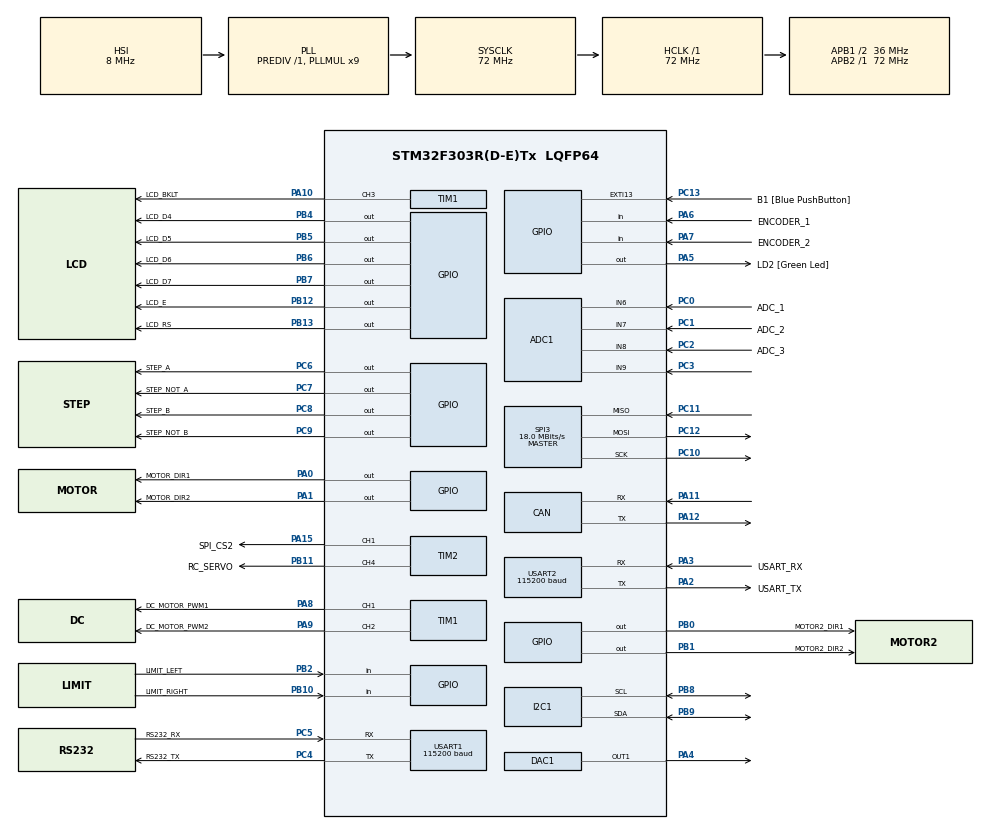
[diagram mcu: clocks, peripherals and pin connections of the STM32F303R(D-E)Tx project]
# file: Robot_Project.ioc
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ADC1.Channel-2\#ChannelRegularConversion=ADC_CHANNEL_6
ADC1.NbrOfConversionFlag=1
ADC1.Offset-2\#ChannelRegularConversion=0
ADC1.OffsetNumber-2\#ChannelRegularConversion=ADC_OFFSET_NONE
ADC1.Rank-2\#ChannelRegularConversion=1
ADC1.SamplingTime-2\#ChannelRegularConversion=ADC_SAMPLETIME_1CYCLE_5
ADC1.SingleDiff-2\#ChannelRegularConversion=ADC_DIFFERENTIAL_ENDED
ADC1.master=1
CAN.CalculateTimeQuantum=444.44444444444446
Dma.Request0=USART2_RX
Dma.Request1=USART1_RX
Dma.USART1_RX.1.Direction=DMA_PERIPH_TO_MEMORY
Dma.USART1_RX.1.Instance=DMA1_Channel5
Dma.USART1_RX.1.MemDataAlignment=DMA_MDATAALIGN_BYTE
Dma.USART1_RX.1.MemInc=DMA_MINC_ENABLE
Dma.USART1_RX.1.Mode=DMA_CIRCULAR
Dma.USART1_RX.1.PeriphDataAlignment=DMA_PDATAALIGN_BYTE
Dma.USART1_RX.1.PeriphInc=DMA_PINC_DISABLE
Dma.USART1_RX.1.Priority=DMA_PRIORITY_LOW
Dma.USART2_RX.0.Direction=DMA_PERIPH_TO_MEMORY
Dma.USART2_RX.0.Instance=DMA1_Channel6
Dma.USART2_RX.0.MemDataAlignment=DMA_MDATAALIGN_BYTE
Dma.USART2_RX.0.MemInc=DMA_MINC_ENABLE
Dma.USART2_RX.0.Mode=DMA_CIRCULAR
Dma.USART2_RX.0.PeriphDataAlignment=DMA_PDATAALIGN_BYTE
Dma.USART2_RX.0.PeriphInc=DMA_PINC_DISABLE
Dma.USART2_RX.0.Priority=DMA_PRIORITY_LOW
Mcu.Family=STM32F3
Mcu.Name=STM32F303R(D-E)Tx
Mcu.Package=LQFP64
NVIC.DMA1_Channel5_IRQn=true\:0\:0\:false\:false\:true\:false
NVIC.DMA1_Channel6_IRQn=true\:0\:0\:false\:false\:true\:false
NVIC.PriorityGroup=NVIC_PRIORITYGROUP_0
PA0.GPIO_Label=MOTOR_DIR1
PA0.Signal=GPIO_Output
PA1.GPIO_Label=MOTOR_DIR2
PA1.Signal=GPIO_Output
PA10.GPIO_Label=LCD_BKLT
PA10.Signal=S_TIM1_CH3
PA11.Mode=Master
PA11.Signal=CAN_RX
PA12.Mode=Master
PA12.Signal=CAN_TX
PA13.GPIO_Label=TMS
PA13.Mode=Serial_Wire
PA13.Signal=SYS_JTMS-SWDIO
PA14.GPIO_Label=TCK
PA14.Mode=Serial_Wire
PA14.Signal=SYS_JTCK-SWCLK
PA15.GPIO_Label=SPI_CS2
PA15.Signal=S_TIM2_CH1_ETR
PA2.GPIO_Label=USART_TX
PA2.GPIO_Mode=GPIO_MODE_AF_PP
PA2.GPIO_PuPd=GPIO_NOPULL
PA2.GPIO_Speed=GPIO_SPEED_FREQ_LOW
PA2.Mode=Asynchronous
PA2.Signal=USART2_TX
PA3.GPIO_Label=USART_RX
PA3.GPIO_Mode=GPIO_MODE_AF_PP
PA3.GPIO_PuPd=GPIO_NOPULL
PA3.GPIO_Speed=GPIO_SPEED_FREQ_LOW
PA3.Mode=Asynchronous
PA3.Signal=USART2_RX
PA4.Signal=COMP_DAC11_group
PA5.GPIO_Label=LD2 [Green Led]
PA5.GPIO_Mode=GPIO_MODE_OUTPUT_PP
PA5.GPIO_PuPd=GPIO_NOPULL
PA5.GPIO_Speed=GPIO_SPEED_FREQ_LOW
PA5.Signal=GPIO_Output
PA6.GPIO_Label=ENCODER_1
PA6.Signal=GPIO_Input
PA7.GPIO_Label=ENCODER_2
PA7.Signal=GPIO_Input
PA8.GPIO_Label=DC_MOTOR_PWM1
PA8.Signal=S_TIM1_CH1
PA9.GPIO_Label=DC_MOTOR_PWM2
PA9.Signal=S_TIM1_CH2
PB0.GPIO_Label=MOTOR2_DIR1
PB0.Signal=GPIO_Output
PB1.GPIO_Label=MOTOR2_DIR2
PB1.Signal=GPIO_Output
PB10.GPIO_Label=LIMIT_RIGHT
PB10.Signal=GPIO_Input
PB11.GPIO_Label=RC_SERVO
PB11.Signal=S_TIM2_CH4
PB12.GPIO_Label=LCD_E
PB12.Signal=GPIO_Output
PB13.GPIO_Label=LCD_RS
PB13.Signal=GPIO_Output
PB2.GPIO_Label=LIMIT_LEFT
PB2.Signal=GPIO_Input
PB3.GPIO_Label=SWO
PB3.Signal=SYS_JTDO-TRACESWO
PB4.GPIO_Label=LCD_D4
PB4.Signal=GPIO_Output
PB5.GPIO_Label=LCD_D5
PB5.Signal=GPIO_Output
PB6.GPIO_Label=LCD_D6
PB6.Signal=GPIO_Output
PB7.GPIO_Label=LCD_D7
PB7.Signal=GPIO_Output
PB8.Mode=I2C
PB8.Signal=I2C1_SCL
PB9.Mode=I2C
PB9.Signal=I2C1_SDA
PC0.GPIO_Label=ADC_1
PC0.Signal=ADCx_IN6
PC1.GPIO_Label=ADC_2
PC1.Signal=ADCx_IN7
PC10.Mode=Full_Duplex_Master
PC10.Signal=SPI3_SCK
PC11.Mode=Full_Duplex_Master
PC11.Signal=SPI3_MISO
PC12.Mode=Full_Duplex_Master
PC12.Signal=SPI3_MOSI
PC13.GPIO_Label=B1 [Blue PushButton]
PC13.GPIO_ModeDefaultEXTI=GPIO_MODE_IT_FALLING
PC13.Signal=GPXTI13
PC14-OSC32_IN.Mode=LSE-External-Oscillator
PC14-OSC32_IN.Signal=RCC_OSC32_IN
PC15-OSC32_OUT.Mode=LSE-External-Oscillator
PC15-OSC32_OUT.Signal=RCC_OSC32_OUT
PC2.GPIO_Label=ADC_3
PC2.Signal=ADCx_IN8
PC3.Signal=ADCx_IN9
PC4.GPIO_Label=RS232_TX
PC4.Mode=Asynchronous
PC4.Signal=USART1_TX
PC5.GPIO_Label=RS232_RX
PC5.Mode=Asynchronous
PC5.Signal=USART1_RX
PC6.GPIO_Label=STEP_A
PC6.Signal=GPIO_Output
PC7.GPIO_Label=STEP_NOT_A
PC7.Signal=GPIO_Output
PC8.GPIO_Label=STEP_B
PC8.Signal=GPIO_Output
PC9.GPIO_Label=STEP_NOT_B
PC9.Signal=GPIO_Output
PD2.Signal=S_TIM3_ETR
PF0-OSC_IN.Mode=HSE-External-Oscillator
PF0-OSC_IN.Signal=RCC_OSC_IN
PF1-OSC_OUT.Mode=HSE-External-Oscillator
PF1-OSC_OUT.Signal=RCC_OSC_OUT
ProjectManager.HeapSize=0x200
ProjectManager.StackSize=0x400
ProjectManager.TargetToolchain=SW4STM32
RCC.AHBFreq_Value=72000000
RCC.APB1CLKDivider=RCC_HCLK_DIV2
RCC.APB1Freq_Value=36000000
RCC.APB1TimFreq_Value=72000000
RCC.APB2Freq_Value=72000000
RCC.APB2TimFreq_Value=72000000
RCC.CortexFreq_Value=72000000
RCC.HCLKFreq_Value=72000000
RCC.HSE_VALUE=8000000
RCC.HSI_VALUE=8000000
RCC.PLLM=8
RCC.PLLMUL=RCC_PLL_MUL9
RCC.PLLN=336
RCC.PLLP=RCC_PLLP_DIV4
RCC.PLLQ=7
RCC.RCC_PLLsource_Clock_Source_FROM_HSE=RCC_HSE_PREDIV_DIV2
RCC.SYSCLKFreq_VALUE=72000000
RCC.SYSCLKSourceVirtual=RCC_SYSCLKSOURCE_PLLCLK
RCC.USBFreq_Value=72000000
SH.ADCx_IN6.0=ADC1_IN6,IN6-Differential
SH.ADCx_IN7.0=ADC1_IN7,IN6-Differential
SH.ADCx_IN8.0=ADC1_IN8,IN8-Differential
SH.ADCx_IN9.0=ADC1_IN9,IN8-Differential
SH.COMP_DAC11_group.0=DAC1_OUT1,DAC_OUT1
SH.S_TIM1_CH1.0=TIM1_CH1,PWM Generation1 CH1
SH.S_TIM1_CH2.0=TIM1_CH2,PWM Generation2 CH2
SH.S_TIM1_CH3.0=TIM1_CH3,PWM Generation3 CH3
SH.S_TIM2_CH1_ETR.0=TIM2_CH1,PWM Generation1 CH1
SH.S_TIM2_CH4.0=TIM2_CH4,PWM Generation4 CH4
SH.S_TIM3_ETR.0=TIM3_ETR
SPI3.CalculateBaudRate=18.0 MBits/s
SPI3.Direction=SPI_DIRECTION_2LINES
SPI3.Mode=SPI_MODE_MASTER
SPI3.VirtualType=VM_MASTER
TIM1.Channel-PWM\ Generation1\ CH1=TIM_CHANNEL_1
TIM1.Channel-PWM\ Generation2\ CH2=TIM_CHANNEL_2
TIM1.Channel-PWM\ Generation3\ CH3=TIM_CHANNEL_3
TIM1.Channel-PWM\ Generation4\ No\ Output=TIM_CHANNEL_4
TIM2.Channel-PWM\ Generation1\ CH1=TIM_CHANNEL_1
TIM2.Channel-PWM\ Generation4\ CH4=TIM_CHANNEL_4
USART1.BaudRate=115200
USART1.VirtualMode-Asynchronous=VM_ASYNC
USART2.BaudRate=115200
USART2.VirtualMode-Asynchronous=VM_ASYNC
VP_TIM1_VS_ClockSourceINT.Mode=Internal
VP_TIM1_VS_no_output4.Mode=PWM Generation4 No Output
VP_TIM2_VS_ClockSourceINT.Mode=Internal
VP_TIM3_VS_ClockSourceINT.Mode=Internal
board=NUCLEO-F303RE

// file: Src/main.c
/**
  ******************************************************************************
  * @file           : main.c
  * @brief          : Main program body
  ******************************************************************************
  ** This notice applies to any and all portions of this file
  * that are not between comment pairs USER CODE BEGIN and
  * USER CODE END. Other portions of this file, whether
  * inserted by the user or by software development tools
  * are owned by their respective copyright owners.
  *
  * COPYRIGHT(c) 2018 STMicroelectronics
  *
  * Redistribution and use in source and binary forms, with or without modification,
  * are permitted provided that the following conditions are met:
  *   1. Redistributions of source code must retain the above copyright notice,
  *      this list of conditions and the following disclaimer.
  *   2. Redistributions in binary form must reproduce the above copyright notice,
  *      this list of conditions and the following disclaimer in the documentation
  *      and/or other materials provided with the distribution.
  *   3. Neither the name of STMicroelectronics nor the names of its contributors
  *      may be used to endorse or promote products derived from this software
  *      without specific prior written permission.
  *
  * THIS SOFTWARE IS PROVIDED BY THE COPYRIGHT HOLDERS AND CONTRIBUTORS "AS IS"
  * AND ANY EXPRESS OR IMPLIED WARRANTIES, INCLUDING, BUT NOT LIMITED TO, THE
  * IMPLIED WARRANTIES OF MERCHANTABILITY AND FITNESS FOR A PARTICULAR PURPOSE ARE
  * DISCLAIMED. IN NO EVENT SHALL THE COPYRIGHT HOLDER OR CONTRIBUTORS BE LIABLE
  * FOR ANY DIRECT, INDIRECT, INCIDENTAL, SPECIAL, EXEMPLARY, OR CONSEQUENTIAL
  * DAMAGES (INCLUDING, BUT NOT LIMITED TO, PROCUREMENT OF SUBSTITUTE GOODS OR
  * SERVICES; LOSS OF USE, DATA, OR PROFITS; OR BUSINESS INTERRUPTION) HOWEVER
  * CAUSED AND ON ANY THEORY OF LIABILITY, WHETHER IN CONTRACT, STRICT LIABILITY,
  * OR TORT (INCLUDING NEGLIGENCE OR OTHERWISE) ARISING IN ANY WAY OUT OF THE USE
  * OF THIS SOFTWARE, EVEN IF ADVISED OF THE POSSIBILITY OF SUCH DAMAGE.
  *
  ******************************************************************************
  */
#include "main.h"
#include "stm32f3xx_hal.h"

/* USER CODE BEGIN Includes */

uint8_t Rxdata[10];

/* USER CODE END Includes */

ADC_HandleTypeDef hadc1;

CAN_HandleTypeDef hcan;

DAC_HandleTypeDef hdac1;

I2C_HandleTypeDef hi2c1;

SPI_HandleTypeDef hspi3;

TIM_HandleTypeDef htim1;
TIM_HandleTypeDef htim2;
TIM_HandleTypeDef htim3;

UART_HandleTypeDef huart1;
UART_HandleTypeDef huart2;
DMA_HandleTypeDef hdma_usart1_rx;
DMA_HandleTypeDef hdma_usart2_rx;

/* USER CODE BEGIN PV */
/* Private variables ---------------------------------------------------------*/

/* USER CODE END PV */

void SystemClock_Config(void);
static void MX_GPIO_Init(void);
static void MX_DMA_Init(void);
static void MX_USART2_UART_Init(void);
static void MX_SPI3_Init(void);
static void MX_I2C1_Init(void);
static void MX_ADC1_Init(void);
static void MX_CAN_Init(void);
static void MX_TIM1_Init(void);
static void MX_DAC1_Init(void);
static void MX_USART1_UART_Init(void);
static void MX_TIM2_Init(void);
static void MX_TIM3_Init(void);

void HAL_TIM_MspPostInit(TIM_HandleTypeDef *htim);
uint8_t USART_Read(USART_TypeDef* USARTx);

/* USER CODE BEGIN PFP */

uint8_t* TxData = ">";
uint8_t* Buffer[100];
uint8_t* empty = "\r";
char rxbyte;

int main(void)
{

  /* MCU Configuration----------------------------------------------------------*/

  /* Reset of all peripherals, Initializes the Flash interface and the Systick. */
  HAL_Init();

  /* Configure the system clock */
  SystemClock_Config();

  /* Initialize all configured peripherals */
  MX_GPIO_Init();
  MX_DMA_Init();
  MX_USART2_UART_Init();
  MX_SPI3_Init();
  MX_I2C1_Init();
  MX_ADC1_Init();
  MX_CAN_Init();
  MX_TIM1_Init();
  MX_DAC1_Init();
  MX_USART1_UART_Init();
  MX_TIM2_Init();
  MX_TIM3_Init();

  //variables
  uint8_t echobit [2];
  int index = 0;

  HAL_UART_Transmit(&huart1, TxData, sizeof(TxData), 1000);

  //HAL_UART_Receive_DMA(&huart2,Rxdata,1);
  while(1) {
      rxbyte = USART_Read(USART1);

      //if the received bit is a delete key
      if (rxbyte == 127) {
          //toggles a light for debug purposes
          HAL_GPIO_TogglePin(GPIOA, GPIO_PIN_5);

          //echo back space to show removal
          HAL_UART_Transmit(&huart1, empty, 2, 1000);

          //set the character that was wrong to null
          Buffer[index - 1] = '\0';

          //index backwards
          index = index - 1;

          //resend the value after deleting
          HAL_UART_Transmit(&huart1, Buffer, sizeof(Buffer), 1000);
      }

      //if the recieved key is enter
      if (rxbyte == '\r' || index == 100) {
          //toggles a light for debug purposes
          //HAL_GPIO_TogglePin(GPIOA, GPIO_PIN_5);
          //adds a new line and end of string to what was sent
          HAL_UART_Transmit(&huart1, "\r\n", 2, 1000);

          //in case you want to see what was sent
          HAL_UART_Transmit(&huart1, Buffer, sizeof(Buffer), 1000);
          HAL_UART_Transmit(&huart1, "\r\n", 2, 1000);

          index = 0;

          //reset buffer
          memset(Buffer, 0, sizeof(Buffer));

      }

      //if recived key is not special case
      if (rxbyte != 127 || rxbyte != '\r') {
          //echo back if no conditions met
          Buffer[index] = rxbyte;
          echobit[0] = Buffer[index];
          HAL_UART_Transmit(&huart1, echobit, 2, 1000);//setting the buffer for whole word and what is echoed back
          index++;
      }
  }

}

void SystemClock_Config(void)
{

  RCC_OscInitTypeDef RCC_OscInitStruct;
  RCC_ClkInitTypeDef RCC_ClkInitStruct;
  RCC_PeriphCLKInitTypeDef PeriphClkInit;

    /**Initializes the CPU, AHB and APB busses clocks
    */
  RCC_OscInitStruct.OscillatorType = RCC_OSCILLATORTYPE_HSI;
  RCC_OscInitStruct.HSIState = RCC_HSI_ON;
  RCC_OscInitStruct.HSICalibrationValue = 16;
  RCC_OscInitStruct.PLL.PLLState = RCC_PLL_ON;
  RCC_OscInitStruct.PLL.PLLSource = RCC_PLLSOURCE_HSI;
  RCC_OscInitStruct.PLL.PLLMUL = RCC_PLL_MUL9;
  RCC_OscInitStruct.PLL.PREDIV = RCC_PREDIV_DIV1;
  if (HAL_RCC_OscConfig(&RCC_OscInitStruct) != HAL_OK)
  {
    _Error_Handler(__FILE__, __LINE__);
  }

    /**Initializes the CPU, AHB and APB busses clocks
    */
  RCC_ClkInitStruct.ClockType = RCC_CLOCKTYPE_HCLK|RCC_CLOCKTYPE_SYSCLK
                              |RCC_CLOCKTYPE_PCLK1|RCC_CLOCKTYPE_PCLK2;
  RCC_ClkInitStruct.SYSCLKSource = RCC_SYSCLKSOURCE_PLLCLK;
  RCC_ClkInitStruct.AHBCLKDivider = RCC_SYSCLK_DIV1;
  RCC_ClkInitStruct.APB1CLKDivider = RCC_HCLK_DIV2;
  RCC_ClkInitStruct.APB2CLKDivider = RCC_HCLK_DIV1;

  if (HAL_RCC_ClockConfig(&RCC_ClkInitStruct, FLASH_LATENCY_2) != HAL_OK)
  {
    _Error_Handler(__FILE__, __LINE__);
  }

  PeriphClkInit.PeriphClockSelection = RCC_PERIPHCLK_USART1|RCC_PERIPHCLK_USART2
                              |RCC_PERIPHCLK_I2C1|RCC_PERIPHCLK_TIM1
                              |RCC_PERIPHCLK_ADC12|RCC_PERIPHCLK_TIM2
                              |RCC_PERIPHCLK_TIM34;
  PeriphClkInit.Usart1ClockSelection = RCC_USART1CLKSOURCE_PCLK2;
  PeriphClkInit.Usart2ClockSelection = RCC_USART2CLKSOURCE_PCLK1;
  PeriphClkInit.Adc12ClockSelection = RCC_ADC12PLLCLK_DIV1;
  PeriphClkInit.I2c1ClockSelection = RCC_I2C1CLKSOURCE_HSI;
  PeriphClkInit.Tim1ClockSelection = RCC_TIM1CLK_HCLK;
  PeriphClkInit.Tim2ClockSelection = RCC_TIM2CLK_HCLK;
  PeriphClkInit.Tim34ClockSelection = RCC_TIM34CLK_HCLK;
  if (HAL_RCCEx_PeriphCLKConfig(&PeriphClkInit) != HAL_OK)
  {
    _Error_Handler(__FILE__, __LINE__);
  }

    /**Configure the Systick interrupt time
    */
  HAL_SYSTICK_Config(HAL_RCC_GetHCLKFreq()/1000);

    /**Configure the Systick
    */
  HAL_SYSTICK_CLKSourceConfig(SYSTICK_CLKSOURCE_HCLK);

  /* SysTick_IRQn interrupt configuration */
  HAL_NVIC_SetPriority(SysTick_IRQn, 0, 0);
}

/* ADC1 init function */
static void MX_ADC1_Init(void)
{

  ADC_MultiModeTypeDef multimode;
  ADC_ChannelConfTypeDef sConfig;

    /**Common config
    */
  hadc1.Instance = ADC1;
  hadc1.Init.ClockPrescaler = ADC_CLOCK_ASYNC_DIV1;
  hadc1.Init.Resolution = ADC_RESOLUTION_12B;
  hadc1.Init.ScanConvMode = ADC_SCAN_DISABLE;
  hadc1.Init.ContinuousConvMode = DISABLE;
  hadc1.Init.DiscontinuousConvMode = DISABLE;
  hadc1.Init.ExternalTrigConvEdge = ADC_EXTERNALTRIGCONVEDGE_NONE;
  hadc1.Init.ExternalTrigConv = ADC_SOFTWARE_START;
  hadc1.Init.DataAlign = ADC_DATAALIGN_RIGHT;
  hadc1.Init.NbrOfConversion = 1;
  hadc1.Init.DMAContinuousRequests = DISABLE;
  hadc1.Init.EOCSelection = ADC_EOC_SINGLE_CONV;
  hadc1.Init.LowPowerAutoWait = DISABLE;
  hadc1.Init.Overrun = ADC_OVR_DATA_OVERWRITTEN;
  if (HAL_ADC_Init(&hadc1) != HAL_OK)
  {
    _Error_Handler(__FILE__, __LINE__);
  }

    /**Configure the ADC multi-mode
    */
  multimode.Mode = ADC_MODE_INDEPENDENT;
  if (HAL_ADCEx_MultiModeConfigChannel(&hadc1, &multimode) != HAL_OK)
  {
    _Error_Handler(__FILE__, __LINE__);
  }

    /**Configure Regular Channel
    */
  sConfig.Channel = ADC_CHANNEL_6;
  sConfig.Rank = ADC_REGULAR_RANK_1;
  sConfig.SingleDiff = ADC_DIFFERENTIAL_ENDED;
  sConfig.SamplingTime = ADC_SAMPLETIME_1CYCLE_5;
  sConfig.OffsetNumber = ADC_OFFSET_NONE;
  sConfig.Offset = 0;
  if (HAL_ADC_ConfigChannel(&hadc1, &sConfig) != HAL_OK)
  {
    _Error_Handler(__FILE__, __LINE__);
  }

}

/* CAN init function */
static void MX_CAN_Init(void)
{

  hcan.Instance = CAN;
  hcan.Init.Prescaler = 16;
  hcan.Init.Mode = CAN_MODE_NORMAL;
  hcan.Init.SyncJumpWidth = CAN_SJW_1TQ;
  hcan.Init.TimeSeg1 = CAN_BS1_1TQ;
  hcan.Init.TimeSeg2 = CAN_BS2_1TQ;
  hcan.Init.TimeTriggeredMode = DISABLE;
  hcan.Init.AutoBusOff = DISABLE;
  hcan.Init.AutoWakeUp = DISABLE;
  hcan.Init.AutoRetransmission = DISABLE;
  hcan.Init.ReceiveFifoLocked = DISABLE;
  hcan.Init.TransmitFifoPriority = DISABLE;
  if (HAL_CAN_Init(&hcan) != HAL_OK)
  {
    _Error_Handler(__FILE__, __LINE__);
  }

}

/* DAC1 init function */
static void MX_DAC1_Init(void)
{

  DAC_ChannelConfTypeDef sConfig;

    /**DAC Initialization
    */
  hdac1.Instance = DAC1;
  if (HAL_DAC_Init(&hdac1) != HAL_OK)
  {
    _Error_Handler(__FILE__, __LINE__);
  }

    /**DAC channel OUT1 config
    */
  sConfig.DAC_Trigger = DAC_TRIGGER_NONE;
  sConfig.DAC_OutputBuffer = DAC_OUTPUTBUFFER_ENABLE;
  if (HAL_DAC_ConfigChannel(&hdac1, &sConfig, DAC_CHANNEL_1) != HAL_OK)
  {
    _Error_Handler(__FILE__, __LINE__);
  }

}

/* I2C1 init function */
static void MX_I2C1_Init(void)
{

  hi2c1.Instance = I2C1;
  hi2c1.Init.Timing = 0x2000090E;
  hi2c1.Init.OwnAddress1 = 0;
  hi2c1.Init.AddressingMode = I2C_ADDRESSINGMODE_7BIT;
  hi2c1.Init.DualAddressMode = I2C_DUALADDRESS_DISABLE;
  hi2c1.Init.OwnAddress2 = 0;
  hi2c1.Init.OwnAddress2Masks = I2C_OA2_NOMASK;
  hi2c1.Init.GeneralCallMode = I2C_GENERALCALL_DISABLE;
  hi2c1.Init.NoStretchMode = I2C_NOSTRETCH_DISABLE;
  if (HAL_I2C_Init(&hi2c1) != HAL_OK)
  {
    _Error_Handler(__FILE__, __LINE__);
  }

    /**Configure Analogue filter
    */
  if (HAL_I2CEx_ConfigAnalogFilter(&hi2c1, I2C_ANALOGFILTER_ENABLE) != HAL_OK)
  {
    _Error_Handler(__FILE__, __LINE__);
  }

    /**Configure Digital filter
    */
  if (HAL_I2CEx_ConfigDigitalFilter(&hi2c1, 0) != HAL_OK)
  {
    _Error_Handler(__FILE__, __LINE__);
  }

}

/* SPI3 init function */
static void MX_SPI3_Init(void)
{

  /* SPI3 parameter configuration*/
  hspi3.Instance = SPI3;
  hspi3.Init.Mode = SPI_MODE_MASTER;
  hspi3.Init.Direction = SPI_DIRECTION_2LINES;
  hspi3.Init.DataSize = SPI_DATASIZE_4BIT;
  hspi3.Init.CLKPolarity = SPI_POLARITY_LOW;
  hspi3.Init.CLKPhase = SPI_PHASE_1EDGE;
  hspi3.Init.NSS = SPI_NSS_SOFT;
  hspi3.Init.BaudRatePrescaler = SPI_BAUDRATEPRESCALER_2;
  hspi3.Init.FirstBit = SPI_FIRSTBIT_MSB;
  hspi3.Init.TIMode = SPI_TIMODE_DISABLE;
  hspi3.Init.CRCCalculation = SPI_CRCCALCULATION_DISABLE;
  hspi3.Init.CRCPolynomial = 7;
  hspi3.Init.CRCLength = SPI_CRC_LENGTH_DATASIZE;
  hspi3.Init.NSSPMode = SPI_NSS_PULSE_ENABLE;
  if (HAL_SPI_Init(&hspi3) != HAL_OK)
  {
    _Error_Handler(__FILE__, __LINE__);
  }

}

/* TIM1 init function */
static void MX_TIM1_Init(void)
{

  TIM_ClockConfigTypeDef sClockSourceConfig;
  TIM_MasterConfigTypeDef sMasterConfig;
  TIM_OC_InitTypeDef sConfigOC;
  TIM_BreakDeadTimeConfigTypeDef sBreakDeadTimeConfig;

  htim1.Instance = TIM1;
  htim1.Init.Prescaler = 0;
  htim1.Init.CounterMode = TIM_COUNTERMODE_UP;
  htim1.Init.Period = 0;
  htim1.Init.ClockDivision = TIM_CLOCKDIVISION_DIV1;
  htim1.Init.RepetitionCounter = 0;
  htim1.Init.AutoReloadPreload = TIM_AUTORELOAD_PRELOAD_DISABLE;
  if (HAL_TIM_Base_Init(&htim1) != HAL_OK)
  {
    _Error_Handler(__FILE__, __LINE__);
  }

  sClockSourceConfig.ClockSource = TIM_CLOCKSOURCE_INTERNAL;
  if (HAL_TIM_ConfigClockSource(&htim1, &sClockSourceConfig) != HAL_OK)
  {
    _Error_Handler(__FILE__, __LINE__);
  }

  if (HAL_TIM_PWM_Init(&htim1) != HAL_OK)
  {
    _Error_Handler(__FILE__, __LINE__);
  }

  sMasterConfig.MasterOutputTrigger = TIM_TRGO_RESET;
  sMasterConfig.MasterOutputTrigger2 = TIM_TRGO2_RESET;
  sMasterConfig.MasterSlaveMode = TIM_MASTERSLAVEMODE_DISABLE;
  if (HAL_TIMEx_MasterConfigSynchronization(&htim1, &sMasterConfig) != HAL_OK)
  {
    _Error_Handler(__FILE__, __LINE__);
  }

  sConfigOC.OCMode = TIM_OCMODE_PWM1;
  sConfigOC.Pulse = 0;
  sConfigOC.OCPolarity = TIM_OCPOLARITY_HIGH;
  sConfigOC.OCNPolarity = TIM_OCNPOLARITY_HIGH;
  sConfigOC.OCFastMode = TIM_OCFAST_DISABLE;
  sConfigOC.OCIdleState = TIM_OCIDLESTATE_RESET;
  sConfigOC.OCNIdleState = TIM_OCNIDLESTATE_RESET;
  if (HAL_TIM_PWM_ConfigChannel(&htim1, &sConfigOC, TIM_CHANNEL_1) != HAL_OK)
  {
    _Error_Handler(__FILE__, __LINE__);
  }

  if (HAL_TIM_PWM_ConfigChannel(&htim1, &sConfigOC, TIM_CHANNEL_2) != HAL_OK)
  {
    _Error_Handler(__FILE__, __LINE__);
  }

  if (HAL_TIM_PWM_ConfigChannel(&htim1, &sConfigOC, TIM_CHANNEL_3) != HAL_OK)
  {
    _Error_Handler(__FILE__, __LINE__);
  }

  if (HAL_TIM_PWM_ConfigChannel(&htim1, &sConfigOC, TIM_CHANNEL_4) != HAL_OK)
  {
    _Error_Handler(__FILE__, __LINE__);
  }

  sBreakDeadTimeConfig.OffStateRunMode = TIM_OSSR_DISABLE;
  sBreakDeadTimeConfig.OffStateIDLEMode = TIM_OSSI_DISABLE;
  sBreakDeadTimeConfig.LockLevel = TIM_LOCKLEVEL_OFF;
  sBreakDeadTimeConfig.DeadTime = 0;
  sBreakDeadTimeConfig.BreakState = TIM_BREAK_DISABLE;
  sBreakDeadTimeConfig.BreakPolarity = TIM_BREAKPOLARITY_HIGH;
  sBreakDeadTimeConfig.BreakFilter = 0;
  sBreakDeadTimeConfig.Break2State = TIM_BREAK2_DISABLE;
  sBreakDeadTimeConfig.Break2Polarity = TIM_BREAK2POLARITY_HIGH;
  sBreakDeadTimeConfig.Break2Filter = 0;
  sBreakDeadTimeConfig.AutomaticOutput = TIM_AUTOMATICOUTPUT_DISABLE;
  if (HAL_TIMEx_ConfigBreakDeadTime(&htim1, &sBreakDeadTimeConfig) != HAL_OK)
  {
    _Error_Handler(__FILE__, __LINE__);
  }

  HAL_TIM_MspPostInit(&htim1);

}

/* TIM2 init function */
static void MX_TIM2_Init(void)
{

  TIM_ClockConfigTypeDef sClockSourceConfig;
  TIM_MasterConfigTypeDef sMasterConfig;
  TIM_OC_InitTypeDef sConfigOC;

  htim2.Instance = TIM2;
  htim2.Init.Prescaler = 0;
  htim2.Init.CounterMode = TIM_COUNTERMODE_UP;
  htim2.Init.Period = 0;
  htim2.Init.ClockDivision = TIM_CLOCKDIVISION_DIV1;
  htim2.Init.AutoReloadPreload = TIM_AUTORELOAD_PRELOAD_DISABLE;
  if (HAL_TIM_Base_Init(&htim2) != HAL_OK)
  {
    _Error_Handler(__FILE__, __LINE__);
  }

  sClockSourceConfig.ClockSource = TIM_CLOCKSOURCE_INTERNAL;
  if (HAL_TIM_ConfigClockSource(&htim2, &sClockSourceConfig) != HAL_OK)
  {
    _Error_Handler(__FILE__, __LINE__);
  }

  if (HAL_TIM_PWM_Init(&htim2) != HAL_OK)
  {
    _Error_Handler(__FILE__, __LINE__);
  }

  sMasterConfig.MasterOutputTrigger = TIM_TRGO_RESET;
  sMasterConfig.MasterSlaveMode = TIM_MASTERSLAVEMODE_DISABLE;
  if (HAL_TIMEx_MasterConfigSynchronization(&htim2, &sMasterConfig) != HAL_OK)
  {
    _Error_Handler(__FILE__, __LINE__);
  }

  sConfigOC.OCMode = TIM_OCMODE_PWM1;
  sConfigOC.Pulse = 0;
  sConfigOC.OCPolarity = TIM_OCPOLARITY_HIGH;
  sConfigOC.OCFastMode = TIM_OCFAST_DISABLE;
  if (HAL_TIM_PWM_ConfigChannel(&htim2, &sConfigOC, TIM_CHANNEL_1) != HAL_OK)
  {
    _Error_Handler(__FILE__, __LINE__);
  }

  if (HAL_TIM_PWM_ConfigChannel(&htim2, &sConfigOC, TIM_CHANNEL_4) != HAL_OK)
  {
    _Error_Handler(__FILE__, __LINE__);
  }

  HAL_TIM_MspPostInit(&htim2);

}

/* TIM3 init function */
static void MX_TIM3_Init(void)
{

  TIM_ClockConfigTypeDef sClockSourceConfig;
  TIM_MasterConfigTypeDef sMasterConfig;

  htim3.Instance = TIM3;
  htim3.Init.Prescaler = 0;
  htim3.Init.CounterMode = TIM_COUNTERMODE_UP;
  htim3.Init.Period = 0;
  htim3.Init.ClockDivision = TIM_CLOCKDIVISION_DIV1;
  htim3.Init.AutoReloadPreload = TIM_AUTORELOAD_PRELOAD_DISABLE;
  if (HAL_TIM_Base_Init(&htim3) != HAL_OK)
  {
    _Error_Handler(__FILE__, __LINE__);
  }

  sClockSourceConfig.ClockSource = TIM_CLOCKSOURCE_INTERNAL;
  if (HAL_TIM_ConfigClockSource(&htim3, &sClockSourceConfig) != HAL_OK)
  {
    _Error_Handler(__FILE__, __LINE__);
  }

  sMasterConfig.MasterOutputTrigger = TIM_TRGO_RESET;
  sMasterConfig.MasterSlaveMode = TIM_MASTERSLAVEMODE_DISABLE;
  if (HAL_TIMEx_MasterConfigSynchronization(&htim3, &sMasterConfig) != HAL_OK)
  {
    _Error_Handler(__FILE__, __LINE__);
  }

}

/* USART1 init function */
static void MX_USART1_UART_Init(void)
{

  huart1.Instance = USART1;
  huart1.Init.BaudRate = 9600;
  huart1.Init.WordLength = UART_WORDLENGTH_8B;
  huart1.Init.StopBits = UART_STOPBITS_1;
  huart1.Init.Parity = UART_PARITY_NONE;
  huart1.Init.Mode = UART_MODE_TX_RX;
  huart1.Init.HwFlowCtl = UART_HWCONTROL_NONE;
  huart1.Init.OverSampling = UART_OVERSAMPLING_16;
  huart1.Init.OneBitSampling = UART_ONE_BIT_SAMPLE_DISABLE;
  huart1.AdvancedInit.AdvFeatureInit = UART_ADVFEATURE_NO_INIT;
  if (HAL_UART_Init(&huart1) != HAL_OK)
  {
    _Error_Handler(__FILE__, __LINE__);
  }

}

/* USART2 init function */
static void MX_USART2_UART_Init(void)
{

  huart2.Instance = USART2;
  huart2.Init.BaudRate = 115200;
  huart2.Init.WordLength = UART_WORDLENGTH_8B;
  huart2.Init.StopBits = UART_STOPBITS_1;
  huart2.Init.Parity = UART_PARITY_NONE;
  huart2.Init.Mode = UART_MODE_TX_RX;
  huart2.Init.HwFlowCtl = UART_HWCONTROL_NONE;
  huart2.Init.OverSampling = UART_OVERSAMPLING_16;
  huart2.Init.OneBitSampling = UART_ONE_BIT_SAMPLE_DISABLE;
  huart2.AdvancedInit.AdvFeatureInit = UART_ADVFEATURE_NO_INIT;

  if (HAL_UART_Init(&huart2) != HAL_OK)
  {
    _Error_Handler(__FILE__, __LINE__);
  }

}

static void MX_DMA_Init(void)
{
  /* DMA controller clock enable */
  __HAL_RCC_DMA1_CLK_ENABLE();

  /* DMA interrupt init */
  /* DMA1_Channel5_IRQn interrupt configuration */
  HAL_NVIC_SetPriority(DMA1_Channel5_IRQn, 0, 0);
  HAL_NVIC_EnableIRQ(DMA1_Channel5_IRQn);
  /* DMA1_Channel6_IRQn interrupt configuration */
  HAL_NVIC_SetPriority(DMA1_Channel6_IRQn, 0, 0);
  HAL_NVIC_EnableIRQ(DMA1_Channel6_IRQn);

}

/** Configure pins as
        * Analog
        * Input
        * Output
        * EVENT_OUT
        * EXTI
*/
static void MX_GPIO_Init(void)
{

  GPIO_InitTypeDef GPIO_InitStruct;

  /* GPIO Ports Clock Enable */
  __HAL_RCC_GPIOC_CLK_ENABLE();
  __HAL_RCC_GPIOF_CLK_ENABLE();
  __HAL_RCC_GPIOA_CLK_ENABLE();
  __HAL_RCC_GPIOB_CLK_ENABLE();
  __HAL_RCC_GPIOD_CLK_ENABLE();

  /*Configure GPIO pin Output Level */
  HAL_GPIO_WritePin(GPIOA, MOTOR_DIR1_Pin|MOTOR_DIR2_Pin|LD2_Pin, GPIO_PIN_RESET);

  /*Configure GPIO pin Output Level */
  HAL_GPIO_WritePin(GPIOB, MOTOR2_DIR1_Pin|MOTOR2_DIR2_Pin|LCD_E_Pin|LCD_RS_Pin
                          |LCD_D4_Pin|LCD_D5_Pin|LCD_D6_Pin|LCD_D7_Pin, GPIO_PIN_RESET);

  /*Configure GPIO pin Output Level */
  HAL_GPIO_WritePin(GPIOC, STEP_A_Pin|STEP_NOT_A_Pin|STEP_B_Pin|STEP_NOT_B_Pin, GPIO_PIN_RESET);

  /*Configure GPIO pin : B1_Pin */
  GPIO_InitStruct.Pin = B1_Pin;
  GPIO_InitStruct.Mode = GPIO_MODE_IT_FALLING;
  GPIO_InitStruct.Pull = GPIO_NOPULL;
  HAL_GPIO_Init(B1_GPIO_Port, &GPIO_InitStruct);

  /*Configure GPIO pins : MOTOR_DIR1_Pin MOTOR_DIR2_Pin LD2_Pin */
  GPIO_InitStruct.Pin = MOTOR_DIR1_Pin|MOTOR_DIR2_Pin|LD2_Pin;
  GPIO_InitStruct.Mode = GPIO_MODE_OUTPUT_PP;
  GPIO_InitStruct.Pull = GPIO_NOPULL;
  GPIO_InitStruct.Speed = GPIO_SPEED_FREQ_LOW;
  HAL_GPIO_Init(GPIOA, &GPIO_InitStruct);

  /*Configure GPIO pins : ENCODER_1_Pin ENCODER_2_Pin */
  GPIO_InitStruct.Pin = ENCODER_1_Pin|ENCODER_2_Pin;
  GPIO_InitStruct.Mode = GPIO_MODE_INPUT;
  GPIO_InitStruct.Pull = GPIO_NOPULL;
  HAL_GPIO_Init(GPIOA, &GPIO_InitStruct);

  /*Configure GPIO pins : MOTOR2_DIR1_Pin MOTOR2_DIR2_Pin LCD_E_Pin LCD_RS_Pin
                           LCD_D4_Pin LCD_D5_Pin LCD_D6_Pin LCD_D7_Pin */
  GPIO_InitStruct.Pin = MOTOR2_DIR1_Pin|MOTOR2_DIR2_Pin|LCD_E_Pin|LCD_RS_Pin
                          |LCD_D4_Pin|LCD_D5_Pin|LCD_D6_Pin|LCD_D7_Pin;
  GPIO_InitStruct.Mode = GPIO_MODE_OUTPUT_PP;
  GPIO_InitStruct.Pull = GPIO_NOPULL;
  GPIO_InitStruct.Speed = GPIO_SPEED_FREQ_LOW;
  HAL_GPIO_Init(GPIOB, &GPIO_InitStruct);

  /*Configure GPIO pins : LIMIT_LEFT_Pin LIMIT_RIGHT_Pin */
  GPIO_InitStruct.Pin = LIMIT_LEFT_Pin|LIMIT_RIGHT_Pin;
  GPIO_InitStruct.Mode = GPIO_MODE_INPUT;
  GPIO_InitStruct.Pull = GPIO_NOPULL;
  HAL_GPIO_Init(GPIOB, &GPIO_InitStruct);

  /*Configure GPIO pins : STEP_A_Pin STEP_NOT_A_Pin STEP_B_Pin STEP_NOT_B_Pin */
  GPIO_InitStruct.Pin = STEP_A_Pin|STEP_NOT_A_Pin|STEP_B_Pin|STEP_NOT_B_Pin;
  GPIO_InitStruct.Mode = GPIO_MODE_OUTPUT_PP;
  GPIO_InitStruct.Pull = GPIO_NOPULL;
  GPIO_InitStruct.Speed = GPIO_SPEED_FREQ_LOW;
  HAL_GPIO_Init(GPIOC, &GPIO_InitStruct);

}

uint8_t USART_Read(USART_TypeDef* USARTx)
{
  while (!(USARTx->ISR & USART_ISR_RXNE));

  return((uint8_t) (USARTx->RDR & 0xFF));
}

void _Error_Handler(char *file, int line)
{
  while(1)
  {
  }
}

/************************ (C) COPYRIGHT STMicroelectronics *****END OF FILE****/
